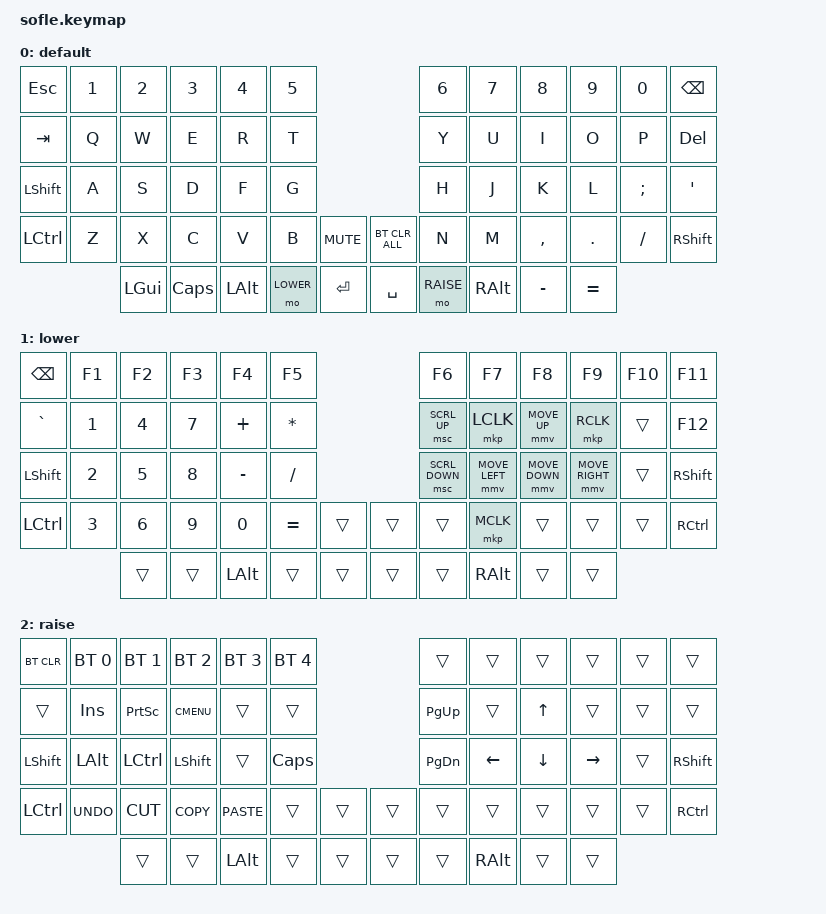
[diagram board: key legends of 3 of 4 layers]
/*
 * Copyright (c) 2020 The ZMK Contributors
 *
 * SPDX-License-Identifier: MIT
 */

#include <behaviors.dtsi>
#include <dt-bindings/zmk/bt.h>
#include <dt-bindings/zmk/ext_power.h>
#include <dt-bindings/zmk/keys.h>
#include <dt-bindings/zmk/pointing.h>
#include <dt-bindings/zmk/rgb.h>

#define BASE 0
#define LOWER 1
#define RAISE 2
#define ADJUST 3

/ {
    // Activate ADJUST layer by pressing raise and lower

    conditional_layers {
        compatible = "zmk,conditional-layers";

        adjust_layer {
            if-layers = <LOWER RAISE>;
            then-layer = <ADJUST>;
        };
    };

    keymap {
        compatible = "zmk,keymap";

        default_layer {
            display-name = "default";
            bindings = <
&kp ESCAPE        &kp N1  &kp N2    &kp N3        &kp N4        &kp N5                                   &kp N6     &kp N7         &kp N8     &kp N9     &kp N0    &kp BACKSPACE
&kp TAB           &kp Q   &kp W     &kp E         &kp R         &kp T                                    &kp Y      &kp U          &kp I      &kp O      &kp P     &kp DELETE
&kp LEFT_SHIFT    &kp A   &kp S     &kp D         &kp F         &kp G                                    &kp H      &kp J          &kp K      &kp L      &kp SEMI  &kp SQT
&kp LEFT_CONTROL  &kp Z   &kp X     &kp C         &kp V         &kp B      &kp C_MUTE    &bt BT_CLR_ALL  &kp N      &kp M          &kp COMMA  &kp DOT    &kp FSLH  &kp RSHFT
                          &kp LGUI  &kp CAPSLOCK  &kp LEFT_ALT  &mo LOWER  &kp RET       &kp SPACE       &mo RAISE  &kp RIGHT_ALT  &kp MINUS  &kp EQUAL
            >;

            sensor-bindings =
                <&inc_dec_kp UP_ARROW DOWN>,
                <&inc_dec_kp RIGHT LEFT>;
        };

        lower_layer {
            display-name = "lower";
            bindings = <
&kp BACKSPACE     &kp F1        &kp F2        &kp F3        &kp F4        &kp F5                       &kp F6          &kp F7          &kp F8          &kp F9           &kp F10  &kp F11
&kp GRAVE         &kp N1        &kp NUMBER_4  &kp NUMBER_7  &kp PLUS      &kp STAR                     &msc SCRL_UP    &mkp LCLK       &mmv MOVE_UP    &mkp RCLK        &trans   &kp F12
&kp LEFT_SHIFT    &kp NUMBER_2  &kp N5        &kp NUMBER_8  &kp MINUS     &kp SLASH                    &msc SCRL_DOWN  &mmv MOVE_LEFT  &mmv MOVE_DOWN  &mmv MOVE_RIGHT  &trans   &kp RIGHT_SHIFT
&kp LEFT_CONTROL  &kp NUMBER_3  &kp NUMBER_6  &kp NUMBER_9  &kp NUMBER_0  &kp EQUAL  &trans    &trans  &trans          &mkp MCLK       &trans          &trans           &trans   &kp RIGHT_CONTROL
                                &trans        &trans        &kp LEFT_ALT  &trans     &trans    &trans  &trans          &kp RIGHT_ALT   &trans          &trans
            >;

            sensor-bindings =
                <&inc_dec_kp C_VOL_UP C_VOL_DN>,
                <&inc_dec_kp C_NEXT C_PREVIOUS>;
        };

        raise_layer {
            display-name = "raise";
            bindings = <
&bt BT_CLR        &bt BT_SEL 0  &bt BT_SEL 1  &bt BT_SEL 2  &bt BT_SEL 3  &bt BT_SEL 4                    &trans     &trans         &trans    &trans     &trans  &trans
&trans            &kp INS       &kp PSCRN     &kp K_CMENU   &trans        &trans                          &kp PG_UP  &trans         &kp UP    &trans     &trans  &trans
&kp LEFT_SHIFT    &kp LALT      &kp LCTRL     &kp LSHFT     &trans        &kp CLCK                        &kp PG_DN  &kp LEFT       &kp DOWN  &kp RIGHT  &trans  &kp RIGHT_SHIFT
&kp LEFT_CONTROL  &kp K_UNDO    &kp K_CUT     &kp K_COPY    &kp K_PASTE   &trans        &trans    &trans  &trans     &trans         &trans    &trans     &trans  &kp RIGHT_CONTROL
                                &trans        &trans        &kp LEFT_ALT  &trans        &trans    &trans  &trans     &kp RIGHT_ALT  &trans    &trans
            >;

            sensor-bindings =
                <&inc_dec_kp C_VOLUME_UP C_VOLUME_DOWN>,
                <&inc_dec_kp END HOME>;
        };

        adjust_layer {
            display-name = "adjust";
            bindings = <
&bt BT_CLR         &bt BT_SEL 0     &bt BT_SEL 1     &bt BT_SEL 2     &bt BT_SEL 3     &bt BT_SEL 4                               &none  &none  &none  &none  &none  &none
&ext_power EP_TOG  &rgb_ug RGB_HUD  &rgb_ug RGB_HUI  &rgb_ug RGB_SAD  &rgb_ug RGB_SAI  &rgb_ug RGB_EFF                            &none  &none  &none  &none  &none  &none
&none              &rgb_ug RGB_BRD  &rgb_ug RGB_BRI  &none            &none            &none                                      &none  &none  &none  &none  &none  &none
&none              &none            &none            &none            &none            &none            &rgb_ug RGB_TOG    &none  &none  &none  &none  &none  &none  &none
                                    &none            &none            &none            &none            &none              &none  &none  &none  &none
            >;
        };
    };
};
